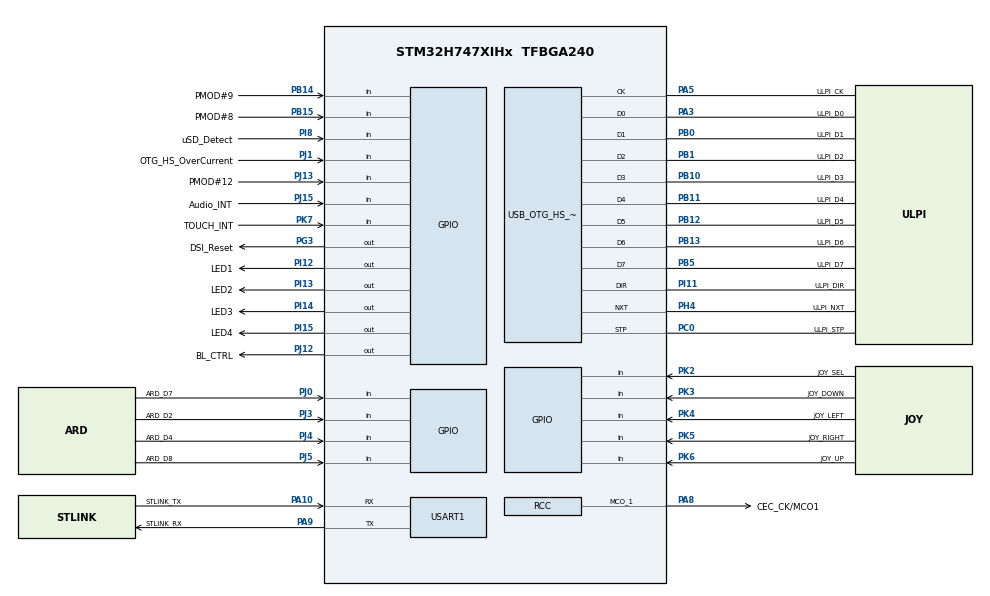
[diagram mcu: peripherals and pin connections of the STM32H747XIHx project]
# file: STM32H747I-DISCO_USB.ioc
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CortexM4.IPs=BDMA,DMA,FATFS_M4\:I,FREERTOS_M4\:I,IWDG2\:I,MDMA,NVIC2\:I,RCC,USB_DEVICE_M4\:I,USB_HOST_M4\:I,WWDG2\:I,DEBUG,PDM2PCM_M4\:I,PWR,RESMGR_UTILITY,SYS_M4\:I,CORTEX_M4\:I,OPENAMP_M4\:I,VREFBUF
CortexM7.IPs=BDMA\:I,DMA\:I,FATFS_M7\:I,FREERTOS_M7\:I,IWDG1\:I,MDMA\:I,NVIC1\:I,RCC\:I,USB_DEVICE_M7\:I,USB_HOST_M7\:I,WWDG1\:I,USART1\:I,CORTEX_M7\:I,DEBUG\:I,PDM2PCM_M7\:I,PWR\:I,RESMGR_UTILITY\:I,SYS\:I,OPENAMP_M7\:I,VREFBUF\:I,USB_OTG_HS\:I
DSI_CKN.Signal=DSIHOST_CKN
DSI_CKP.Signal=DSIHOST_CKP
DSI_D0N.Signal=DSIHOST_D0N
DSI_D0P.Signal=DSIHOST_D0P
DSI_D1N.Signal=DSIHOST_D1N
DSI_D1P.Signal=DSIHOST_D1P
Mcu.Family=STM32H7
Mcu.Name=STM32H747XIHx
Mcu.Package=TFBGA240
NVIC1.OTG_HS_EP1_IN_IRQn=true\:0\:0\:false\:false\:true\:true\:true\:true
NVIC1.OTG_HS_EP1_OUT_IRQn=true\:0\:0\:false\:false\:true\:true\:true\:true
NVIC1.OTG_HS_IRQn=true\:0\:0\:false\:false\:true\:true\:true\:true
NVIC1.PriorityGroup=NVIC_PRIORITYGROUP_4
NVIC2.PriorityGroup=NVIC_PRIORITYGROUP_4
PA0_C.GPIO_Label=ARD_A2
PA0_C.PinAttribute=CortexM4
PA0_C.Signal=ADCx_INP0
PA1.GPIO_Label=ETH_REF_CLK
PA1.PinAttribute=CortexM4
PA1.Signal=ETH_REF_CLK
PA10.GPIO_Label=STLINK_TX
PA10.Mode=Asynchronous
PA10.PinAttribute=CortexM7
PA10.Signal=USART1_RX
PA11.GPIO_Label=PMOD\#1
PA11.PinAttribute=CortexM4
PA11.Signal=SPI2_NSS
PA12.GPIO_Label=SPI2_SCK
PA12.PinAttribute=CortexM4
PA12.Signal=SPI2_SCK
PA1_C.GPIO_Label=ARD_A3
PA1_C.PinAttribute=CortexM4
PA1_C.Signal=ADCx_INP1
PA2.GPIO_Label=ETH_MDIO
PA2.PinAttribute=CortexM4
PA2.Signal=ETH_MDIO
PA3.GPIO_Label=ULPI_D0
PA3.Mode=Device_HS
PA3.PinAttribute=CortexM7
PA3.Signal=USB_OTG_HS_ULPI_D0
PA5.GPIO_Label=ULPI_CK
PA5.Mode=Device_HS
PA5.PinAttribute=CortexM7
PA5.Signal=USB_OTG_HS_ULPI_CK
PA7.GPIO_Label=ETH_CRS_DV
PA7.PinAttribute=CortexM4
PA7.Signal=ETH_CRS_DV
PA8.GPIO_Label=CEC_CK/MCO1
PA8.Mode=Clock-out-1
PA8.PinAttribute=CortexM7
PA8.Signal=RCC_MCO_1
PA9.GPIO_Label=STLINK_RX
PA9.Mode=Asynchronous
PA9.PinAttribute=CortexM7
PA9.Signal=USART1_TX
PB0.GPIO_Label=ULPI_D1
PB0.Mode=Device_HS
PB0.PinAttribute=CortexM7
PB0.Signal=USB_OTG_HS_ULPI_D1
PB1.GPIO_Label=ULPI_D2
PB1.Mode=Device_HS
PB1.PinAttribute=CortexM7
PB1.Signal=USB_OTG_HS_ULPI_D2
PB10.GPIO_Label=ULPI_D3
PB10.Mode=Device_HS
PB10.PinAttribute=CortexM7
PB10.Signal=USB_OTG_HS_ULPI_D3
PB11.GPIO_Label=ULPI_D4
PB11.Mode=Device_HS
PB11.PinAttribute=CortexM7
PB11.Signal=USB_OTG_HS_ULPI_D4
PB12.GPIO_Label=ULPI_D5
PB12.Mode=Device_HS
PB12.PinAttribute=CortexM7
PB12.Signal=USB_OTG_HS_ULPI_D5
PB13.GPIO_Label=ULPI_D6
PB13.Mode=Device_HS
PB13.PinAttribute=CortexM7
PB13.Signal=USB_OTG_HS_ULPI_D6
PB14.GPIO_Label=PMOD\#9
PB14.PinAttribute=Free
PB14.Signal=GPIO_Input
PB15.GPIO_Label=PMOD\#8
PB15.PinAttribute=Free
PB15.Signal=GPIO_Input
PB2.GPIO_Label=QSPI_CLK
PB2.PinAttribute=CortexM4
PB2.Signal=QUADSPI_CLK
PB5.GPIO_Label=ULPI_D7
PB5.Mode=Device_HS
PB5.PinAttribute=CortexM7
PB5.Signal=USB_OTG_HS_ULPI_D7
PB6.GPIO_Label=HDMI_CEC
PB6.PinAttribute=CortexM4
PB6.Signal=CEC
PC0.GPIO_Label=ULPI_STP
PC0.Mode=Device_HS
PC0.PinAttribute=CortexM7
PC0.Signal=USB_OTG_HS_ULPI_STP
PC1.GPIO_Label=ETH_MDC/SAI4_D1
PC1.PinAttribute=CortexM4
PC1.Signal=ETH_MDC
PC10.GPIO_Label=SDIO1_D2
PC10.PinAttribute=CortexM4
PC10.Signal=SDMMC1_D2
PC12.GPIO_Label=SDIO1_CK
PC12.PinAttribute=CortexM4
PC12.Signal=SDMMC1_CK
PC13.GPIO_Label=B2 [Wakeup Button]
PC13.PinAttribute=CortexM4
PC13.Signal=RTC_TAMP1
PC14-OSC32_IN\ (OSC32_IN).GPIO_Label=OSC32_IN
PC14-OSC32_IN\ (OSC32_IN).Mode=LSE-External-Oscillator
PC14-OSC32_IN\ (OSC32_IN).PinAttribute=CortexM7
PC14-OSC32_IN\ (OSC32_IN).Signal=RCC_OSC32_IN
PC15-OSC32_OUT\ (OSC32_OUT).GPIO_Label=OSC32_OUT
PC15-OSC32_OUT\ (OSC32_OUT).Mode=LSE-External-Oscillator
PC15-OSC32_OUT\ (OSC32_OUT).PinAttribute=CortexM7
PC15-OSC32_OUT\ (OSC32_OUT).Signal=RCC_OSC32_OUT
PC2.GPIO_Label=PMOD\#3
PC2.PinAttribute=CortexM4
PC2.Signal=SPI2_MISO
PC2_C.GPIO_Label=ARD_A4
PC2_C.PinAttribute=CortexM4
PC2_C.Signal=ADC3_INP0
PC3.GPIO_Label=PMOD\#2
PC3.PinAttribute=CortexM4
PC3.Signal=SPI2_MOSI
PC3_C.GPIO_Label=ARD_A5
PC3_C.PinAttribute=CortexM4
PC3_C.Signal=ADC3_INP1
PC4.GPIO_Label=ETH_RXD0
PC4.PinAttribute=CortexM4
PC4.Signal=ETH_RXD0
PC5.GPIO_Label=ETH_RXD1
PC5.PinAttribute=CortexM4
PC5.Signal=ETH_RXD1
PC8.GPIO_Label=SDIO1_D0
PC8.PinAttribute=CortexM4
PC8.Signal=SDMMC1_D0
PD0.GPIO_Label=FMC_D2
PD0.PinAttribute=CortexM4
PD0.Signal=FMC_D2_DA2
PD1.GPIO_Label=FMC_D3
PD1.PinAttribute=CortexM4
PD1.Signal=FMC_D3_DA3
PD10.GPIO_Label=FMC_D15
PD10.PinAttribute=CortexM4
PD10.Signal=FMC_D15_DA15
PD11.GPIO_Label=QSPI_BK1_IO0
PD11.PinAttribute=CortexM4
PD11.Signal=QUADSPI_BK1_IO0
PD12.Signal=I2C4_SCL
PD13.Signal=I2C4_SDA
PD14.GPIO_Label=FMC_D0
PD14.PinAttribute=CortexM4
PD14.Signal=FMC_D0_DA0
PD15.GPIO_Label=FMC_D1
PD15.PinAttribute=CortexM4
PD15.Signal=FMC_D1_DA1
PD2.GPIO_Label=SDIO1_CMD
PD2.PinAttribute=CortexM4
PD2.Signal=SDMMC1_CMD
PD7.GPIO_Label=SPDIF_RX0
PD7.PinAttribute=CortexM4
PD7.Signal=SPDIFRX1_IN0
PD8.GPIO_Label=FMC_D13
PD8.PinAttribute=CortexM4
PD8.Signal=FMC_D13_DA13
PD9.GPIO_Label=FMC_D14
PD9.PinAttribute=CortexM4
PD9.Signal=FMC_D14_DA14
PE0.GPIO_Label=FMC_NBL0
PE0.PinAttribute=CortexM4
PE0.Signal=FMC_NBL0
PE1.GPIO_Label=FMC_NBL1
PE1.PinAttribute=CortexM4
PE1.Signal=FMC_NBL1
PE10.GPIO_Label=FMC_D7
PE10.PinAttribute=CortexM4
PE10.Signal=FMC_D7_DA7
PE11.GPIO_Label=FMC_D8
PE11.PinAttribute=CortexM4
PE11.Signal=FMC_D8_DA8
PE12.GPIO_Label=FMC_D9
PE12.PinAttribute=CortexM4
PE12.Signal=FMC_D9_DA9
PE13.GPIO_Label=FMC_D10
PE13.PinAttribute=CortexM4
PE13.Signal=FMC_D10_DA10
PE14.GPIO_Label=FMC_D11
PE14.PinAttribute=CortexM4
PE14.Signal=FMC_D11_DA11
PE15.GPIO_Label=FMC_D12
PE15.PinAttribute=CortexM4
PE15.Signal=FMC_D12_DA12
PE3.GPIO_Label=SAI1_SD_B
PE3.PinAttribute=CortexM4
PE3.Signal=SAI1_SD_B
PE4.GPIO_Label=SAI1_FS_A
PE4.PinAttribute=CortexM4
PE4.Signal=SAI1_FS_A
PE5.GPIO_Label=SAI1_SCK_A
PE5.PinAttribute=CortexM4
PE5.Signal=SAI1_SCK_A
PE6.GPIO_Label=SAI1_SD_A
PE6.PinAttribute=CortexM4
PE6.Signal=SAI1_SD_A
PE7.GPIO_Label=FMC_D4
PE7.PinAttribute=CortexM4
PE7.Signal=FMC_D4_DA4
PE8.GPIO_Label=FMC_D5
PE8.PinAttribute=CortexM4
PE8.Signal=FMC_D5_DA5
PE9.GPIO_Label=FMC_D6
PE9.PinAttribute=CortexM4
PE9.Signal=FMC_D6_DA6
PF0.GPIO_Label=FMC_A0
PF0.PinAttribute=CortexM4
PF0.Signal=FMC_A0
PF1.GPIO_Label=FMC_A1
PF1.PinAttribute=CortexM4
PF1.Signal=FMC_A1
PF10.GPIO_Label=ARD_A1
PF10.PinAttribute=CortexM4
PF10.Signal=ADC3_INP6
PF11.GPIO_Label=FMC_SDRAS
PF11.PinAttribute=CortexM4
PF11.Signal=FMC_SDNRAS
PF12.GPIO_Label=FMC_A6
PF12.PinAttribute=CortexM4
PF12.Signal=FMC_A6
PF13.GPIO_Label=FMC_A7
PF13.PinAttribute=CortexM4
PF13.Signal=FMC_A7
PF14.GPIO_Label=FMC_A8
PF14.PinAttribute=CortexM4
PF14.Signal=FMC_A8
PF15.GPIO_Label=FMC_A9
PF15.PinAttribute=CortexM4
PF15.Signal=FMC_A9
PF2.GPIO_Label=FMC_A2
PF2.PinAttribute=CortexM4
PF2.Signal=FMC_A2
PF3.GPIO_Label=FMC_A3
PF3.PinAttribute=CortexM4
PF3.Signal=FMC_A3
PF4.GPIO_Label=FMC_A4
PF4.PinAttribute=CortexM4
PF4.Signal=FMC_A4
PF5.GPIO_Label=FMC_A5
PF5.PinAttribute=CortexM4
PF5.Signal=FMC_A5
PF6.GPIO_Label=QSPI_BK1_IO3
PF6.PinAttribute=CortexM4
PF6.Signal=QUADSPI_BK1_IO3
PF7.GPIO_Label=QSPI_BK1_IO2
PF7.PinAttribute=CortexM4
PF7.Signal=QUADSPI_BK1_IO2
PF8.GPIO_Label=PMOD\#14/ARD_D3
PF8.PinAttribute=CortexM4
PF8.Signal=S_TIM13_CH1
PF9.GPIO_Label=QSPI_BK1_IO1
PF9.PinAttribute=CortexM4
PF9.Signal=QUADSPI_BK1_IO1
PG0.GPIO_Label=FMC_A10
PG0.PinAttribute=CortexM4
PG0.Signal=FMC_A10
PG1.GPIO_Label=FMC_A11
PG1.PinAttribute=CortexM4
PG1.Signal=FMC_A11
PG11.GPIO_Label=ETH_TX_EN
PG11.PinAttribute=CortexM4
PG11.Signal=ETH_TX_EN
PG12.GPIO_Label=ETH_TXD1
PG12.PinAttribute=CortexM4
PG12.Signal=ETH_TXD1
PG13.GPIO_Label=ETH_TXD0
PG13.PinAttribute=CortexM4
PG13.Signal=ETH_TXD0
PG14.GPIO_Label=QSPI_BK2_IO3
PG14.PinAttribute=CortexM4
PG14.Signal=QUADSPI_BK2_IO3
PG15.GPIO_Label=FMC_SDCAS
PG15.PinAttribute=CortexM4
PG15.Signal=FMC_SDNCAS
PG2.GPIO_Label=FMC_A12
PG2.PinAttribute=CortexM4
PG2.Signal=FMC_A12
PG3.GPIO_Label=DSI_Reset
PG3.PinAttribute=Free
PG3.Signal=GPIO_Output
PG4.GPIO_Label=FMC_BA0
PG4.PinAttribute=CortexM4
PG4.Signal=FMC_A14_BA0
PG6.GPIO_Label=QSPI_BK1_NCS
PG6.PinAttribute=CortexM4
PG6.Signal=QUADSPI_BK1_NCS
PG7.GPIO_Label=SAI1_MCLK_A
PG7.PinAttribute=CortexM4
PG7.Signal=SAI1_MCLK_A
PG8.GPIO_Label=FMC_SDCLK
PG8.PinAttribute=CortexM4
PG8.Signal=FMC_SDCLK
PG9.GPIO_Label=QSPI_BK2_IO2
PG9.PinAttribute=CortexM4
PG9.Signal=QUADSPI_BK2_IO2
PH0-OSC_IN\ (PH0).GPIO_Label=OSC_IN
PH0-OSC_IN\ (PH0).Mode=HSE-External-Oscillator
PH0-OSC_IN\ (PH0).PinAttribute=CortexM7
PH0-OSC_IN\ (PH0).Signal=RCC_OSC_IN
PH1-OSC_OUT\ (PH1).GPIO_Label=OSC_OUT
PH1-OSC_OUT\ (PH1).Mode=HSE-External-Oscillator
PH1-OSC_OUT\ (PH1).PinAttribute=CortexM7
PH1-OSC_OUT\ (PH1).Signal=RCC_OSC_OUT
PH10.GPIO_Label=FMC_D18
PH10.PinAttribute=CortexM4
PH10.Signal=FMC_D18
PH11.GPIO_Label=FMC_D19
PH11.PinAttribute=CortexM4
PH11.Signal=FMC_D19
PH12.GPIO_Label=FMC_D20
PH12.PinAttribute=CortexM4
PH12.Signal=FMC_D20
PH13.GPIO_Label=FMC_D21
PH13.PinAttribute=CortexM4
PH13.Signal=FMC_D21
PH14.GPIO_Label=FMC_D22
PH14.PinAttribute=CortexM4
PH14.Signal=FMC_D22
PH15.GPIO_Label=FMC_D23
PH15.PinAttribute=CortexM4
PH15.Signal=FMC_D23
PH2.GPIO_Label=QSPI_BK2_IO0
PH2.PinAttribute=CortexM4
PH2.Signal=QUADSPI_BK2_IO0
PH3.GPIO_Label=QSPI_BK2_IO1
PH3.PinAttribute=CortexM4
PH3.Signal=QUADSPI_BK2_IO1
PH4.GPIO_Label=ULPI_NXT
PH4.Mode=Device_HS
PH4.PinAttribute=CortexM7
PH4.Signal=USB_OTG_HS_ULPI_NXT
PH5.GPIO_Label=FMC_SDNWE
PH5.PinAttribute=CortexM4
PH5.Signal=FMC_SDNWE
PH6.GPIO_Label=FMC_SDNE1
PH6.PinAttribute=CortexM4
PH6.Signal=FMC_SDNE1
PH7.GPIO_Label=FMC_SDCKE1
PH7.PinAttribute=CortexM4
PH7.Signal=FMC_SDCKE1
PH8.GPIO_Label=FMC_D16
PH8.PinAttribute=CortexM4
PH8.Signal=FMC_D16
PH9.GPIO_Label=FMC_D17
PH9.PinAttribute=CortexM4
PH9.Signal=FMC_D17
PI0.GPIO_Label=FMC_D24
PI0.PinAttribute=CortexM4
PI0.Signal=FMC_D24
PI1.GPIO_Label=FMC_D25
PI1.PinAttribute=CortexM4
PI1.Signal=FMC_D25
PI10.GPIO_Label=FMC_D31
PI10.PinAttribute=CortexM4
PI10.Signal=FMC_D31
PI11.GPIO_Label=ULPI_DIR
PI11.Mode=Device_HS
PI11.PinAttribute=CortexM7
PI11.Signal=USB_OTG_HS_ULPI_DIR
PI12.GPIO_Label=LED1
PI12.PinAttribute=Free
PI12.Signal=GPIO_Output
PI13.GPIO_Label=LED2
PI13.PinAttribute=Free
PI13.Signal=GPIO_Output
PI14.GPIO_Label=LED3
PI14.PinAttribute=Free
PI14.Signal=GPIO_Output
PI15.GPIO_Label=LED4
PI15.PinAttribute=Free
PI15.Signal=GPIO_Output
PI2.GPIO_Label=FMC_D26
PI2.PinAttribute=CortexM4
PI2.Signal=FMC_D26
PI3.GPIO_Label=FMC_D27
PI3.PinAttribute=CortexM4
PI3.Signal=FMC_D27
PI4.GPIO_Label=FMC_NBL2
PI4.PinAttribute=CortexM4
PI4.Signal=FMC_NBL2
PI5.GPIO_Label=FMC_NBL3
PI5.PinAttribute=CortexM4
PI5.Signal=FMC_NBL3
PI6.GPIO_Label=FMC_D28
PI6.PinAttribute=CortexM4
PI6.Signal=FMC_D28
PI7.GPIO_Label=FMC_D29
PI7.PinAttribute=CortexM4
PI7.Signal=FMC_D29
PI8.GPIO_Label=uSD_Detect
PI8.PinAttribute=Free
PI8.Signal=GPIO_Input
PI9.GPIO_Label=FMC_D30
PI9.PinAttribute=CortexM4
PI9.Signal=FMC_D30
PJ0.GPIO_Label=ARD_D7
PJ0.PinAttribute=Free
PJ0.Signal=GPIO_Input
PJ1.GPIO_Label=OTG_HS_OverCurrent
PJ1.PinAttribute=Free
PJ1.Signal=GPIO_Input
PJ10.GPIO_Label=ARD_D11
PJ10.PinAttribute=CortexM4
PJ10.Signal=SPI5_MOSI
PJ11.GPIO_Label=ARD_D12
PJ11.PinAttribute=CortexM4
PJ11.Signal=SPI5_MISO
PJ12.GPIO_Label=BL_CTRL
PJ12.PinAttribute=Free
PJ12.Signal=GPIO_Output
PJ13.GPIO_Label=PMOD\#12
PJ13.PinAttribute=Free
PJ13.Signal=GPIO_Input
PJ15.GPIO_Label=Audio_INT
PJ15.PinAttribute=Free
PJ15.Signal=GPIO_Input
PJ2.GPIO_Label=DSI_TE
PJ2.Signal=DSIHOST_TE
PJ3.GPIO_Label=ARD_D2
PJ3.PinAttribute=Free
PJ3.Signal=GPIO_Input
PJ4.GPIO_Label=ARD_D4
PJ4.PinAttribute=Free
PJ4.Signal=GPIO_Input
PJ5.GPIO_Label=ARD_D8
PJ5.PinAttribute=Free
PJ5.Signal=GPIO_Input
PJ6.GPIO_Label=ARD_D9
PJ6.PinAttribute=CortexM4
PJ6.Signal=S_TIM8_CH2
PJ7.GPIO_Label=ARD_D6
PJ7.PinAttribute=CortexM4
PJ7.Signal=TIM8_CH2N
PJ8.GPIO_Label=ARD_D1
PJ8.PinAttribute=CortexM4
PJ8.Signal=UART8_TX
PJ9.GPIO_Label=ARD_D0
PJ9.PinAttribute=CortexM4
PJ9.Signal=UART8_RX
PK0.GPIO_Label=ARD_D13
PK0.PinAttribute=CortexM4
PK0.Signal=SPI5_SCK
PK1.GPIO_Label=ARD_D10
PK1.PinAttribute=CortexM4
PK1.Signal=SPI5_NSS
PK2.GPIO_Label=JOY_SEL
PK2.PinAttribute=Free
PK2.Signal=GPIO_Input
PK3.GPIO_Label=JOY_DOWN
PK3.PinAttribute=Free
PK3.Signal=GPIO_Input
PK4.GPIO_Label=JOY_LEFT
PK4.PinAttribute=Free
PK4.Signal=GPIO_Input
PK5.GPIO_Label=JOY_RIGHT
PK5.PinAttribute=Free
PK5.Signal=GPIO_Input
PK6.GPIO_Label=JOY_UP
PK6.PinAttribute=Free
PK6.Signal=GPIO_Input
PK7.GPIO_Label=TOUCH_INT
PK7.PinAttribute=Free
PK7.Signal=GPIO_Input
ProjectManager.HeapSize=M4-0x200,M7-0x200
ProjectManager.StackSize=M4-0x400,M7-0x400
ProjectManager.TargetToolchain=STM32CubeIDE
RCC.ADCFreq_Value=75000000
RCC.APB1Freq_Value=64000000
RCC.APB2Freq_Value=64000000
RCC.APB3Freq_Value=64000000
RCC.APB4Freq_Value=64000000
RCC.CortexFreq_Value=64000000
RCC.DIVM1=5
RCC.DIVM2=2
RCC.DIVN1=48
RCC.DIVN2=12
RCC.DIVQ1=5
RCC.HCLKFreq_Value=64000000
RCC.PLL2FRACN=0
RCC.PLL3FRACN=0
RCC.PLLFRACN=0
RCC.PWR_Regulator_Voltage_Scale=PWR_REGULATOR_VOLTAGE_SCALE1
RCC.SYSCLKFreq_VALUE=64000000
RCC.SupplySource=PWR_DIRECT_SMPS_SUPPLY
RCC.USBFreq_Value=48000000
SH.ADCx_INP0.0=ADC1_INP0
SH.ADCx_INP1.0=ADC1_INP1
SH.FMC_A0.0=FMC_A0
SH.FMC_A1.0=FMC_A1
SH.FMC_A10.0=FMC_A10
SH.FMC_A11.0=FMC_A11
SH.FMC_A12.0=FMC_A12
SH.FMC_A14_BA0.0=FMC_BA0
SH.FMC_A2.0=FMC_A2
SH.FMC_A3.0=FMC_A3
SH.FMC_A4.0=FMC_A4
SH.FMC_A5.0=FMC_A5
SH.FMC_A6.0=FMC_A6
SH.FMC_A7.0=FMC_A7
SH.FMC_A8.0=FMC_A8
SH.FMC_A9.0=FMC_A9
SH.FMC_D0_DA0.0=FMC_D0
SH.FMC_D10_DA10.0=FMC_D10
SH.FMC_D11_DA11.0=FMC_D11
SH.FMC_D12_DA12.0=FMC_D12
SH.FMC_D13_DA13.0=FMC_D13
SH.FMC_D14_DA14.0=FMC_D14
SH.FMC_D15_DA15.0=FMC_D15
SH.FMC_D16.0=FMC_D16
SH.FMC_D17.0=FMC_D17
SH.FMC_D18.0=FMC_D18
SH.FMC_D19.0=FMC_D19
SH.FMC_D1_DA1.0=FMC_D1
SH.FMC_D20.0=FMC_D20
SH.FMC_D21.0=FMC_D21
SH.FMC_D22.0=FMC_D22
SH.FMC_D23.0=FMC_D23
SH.FMC_D24.0=FMC_D24
SH.FMC_D25.0=FMC_D25
SH.FMC_D26.0=FMC_D26
SH.FMC_D27.0=FMC_D27
SH.FMC_D28.0=FMC_D28
SH.FMC_D29.0=FMC_D29
SH.FMC_D2_DA2.0=FMC_D2
SH.FMC_D30.0=FMC_D30
SH.FMC_D31.0=FMC_D31
SH.FMC_D3_DA3.0=FMC_D3
SH.FMC_D4_DA4.0=FMC_D4
SH.FMC_D5_DA5.0=FMC_D5
SH.FMC_D6_DA6.0=FMC_D6
SH.FMC_D7_DA7.0=FMC_D7
SH.FMC_D8_DA8.0=FMC_D8
SH.FMC_D9_DA9.0=FMC_D9
SH.FMC_NBL0.0=FMC_NBL0
SH.FMC_NBL1.0=FMC_NBL1
SH.FMC_NBL2.0=FMC_NBL2
SH.FMC_NBL3.0=FMC_NBL3
SH.FMC_SDCLK.0=FMC_SDCLK
SH.FMC_SDNCAS.0=FMC_SDNCAS
SH.FMC_SDNRAS.0=FMC_SDNRAS
SH.FMC_SDNWE.0=FMC_SDNWE
SH.S_TIM13_CH1.0=TIM13_CH1
SH.S_TIM8_CH2.0=TIM8_CH2
USART1.VirtualMode-Asynchronous=VM_ASYNC
USB_DEVICE_M7.CLASS_NAME_HS=CDC
USB_DEVICE_M7.VirtualMode-CDC_HS=Cdc
USB_DEVICE_M7.VirtualModeHS=Cdc_HS
USB_OTG_HS.VirtualMode-Device_HS=Device_HS
VP_SYS_M4_VS_Systick.Mode=SysTick
VP_USB_DEVICE_M7_VS_USB_DEVICE_CDC_HS.Mode=CDC_HS
board=STM32H747I-DISCO

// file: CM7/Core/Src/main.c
/* USER CODE BEGIN Header */
/**
  ******************************************************************************
  * @file           : main.c
  * @brief          : Main program body
  ******************************************************************************
  * @attention
  *
  * Copyright (c) 2022 STMicroelectronics.
  * All rights reserved.
  *
  * This software is licensed under terms that can be found in the LICENSE file
  * in the root directory of this software component.
  * If no LICENSE file comes with this software, it is provided AS-IS.
  *
  ******************************************************************************
  */
/* USER CODE END Header */
#include "main.h"
#include "usb_device.h"

/* USER CODE BEGIN PD */

#ifndef HSEM_ID_0
#define HSEM_ID_0 (0U) /* HW semaphore 0*/
#endif
/* USER CODE END PD */

UART_HandleTypeDef huart1;

void SystemClock_Config(void);
static void MX_GPIO_Init(void);
static void MX_USART1_UART_Init(void);

int main(void)
{
  /* USER CODE BEGIN 1 */
	uint8_t buffer[] = "Hello World\r\n";
  /* USER CODE END 1 */
/* USER CODE BEGIN Boot_Mode_Sequence_0 */
  int32_t timeout;
/* USER CODE END Boot_Mode_Sequence_0 */

/* USER CODE BEGIN Boot_Mode_Sequence_1 */
  /* Wait until CPU2 boots and enters in stop mode or timeout*/

/* USER CODE END Boot_Mode_Sequence_1 */
  /* MCU Configuration--------------------------------------------------------*/

  /* Reset of all peripherals, Initializes the Flash interface and the Systick. */
  HAL_Init();

  /* Configure the system clock */
  SystemClock_Config();
/* USER CODE BEGIN Boot_Mode_Sequence_2 */
/* When system initialization is finished, Cortex-M7 will release Cortex-M4 by means of
HSEM notification */
/*HW semaphore Clock enable*/
__HAL_RCC_HSEM_CLK_ENABLE();
/*Take HSEM */
HAL_HSEM_FastTake(HSEM_ID_0);
/*Release HSEM in order to notify the CPU2(CM4)*/
HAL_HSEM_Release(HSEM_ID_0,0);
/* wait until CPU2 wakes up from stop mode */

/* USER CODE END Boot_Mode_Sequence_2 */

  /* USER CODE BEGIN SysInit */
extern uint8_t CDC_Transmit_HS(uint8_t* Buf, uint16_t Len);
  /* USER CODE END SysInit */

  /* Initialize all configured peripherals */
  MX_GPIO_Init();
  MX_USART1_UART_Init();
  MX_USB_DEVICE_Init();

  /* Infinite loop */
  while (1)
  {
	  CDC_Transmit_HS(buffer, sizeof(buffer));
	  HAL_Delay(1000);
  }
}

void SystemClock_Config(void)
{
  RCC_OscInitTypeDef RCC_OscInitStruct = {0};
  RCC_ClkInitTypeDef RCC_ClkInitStruct = {0};

  /** Supply configuration update enable
  */
  HAL_PWREx_ConfigSupply(PWR_DIRECT_SMPS_SUPPLY);

  /** Configure the main internal regulator output voltage
  */
  __HAL_PWR_VOLTAGESCALING_CONFIG(PWR_REGULATOR_VOLTAGE_SCALE1);

  //while(!__HAL_PWR_GET_FLAG(PWR_FLAG_VOSRDY)) {}

  /** Initializes the RCC Oscillators according to the specified parameters
  * in the RCC_OscInitTypeDef structure.
  */
  RCC_OscInitStruct.OscillatorType = RCC_OSCILLATORTYPE_HSI|RCC_OSCILLATORTYPE_HSE;
  RCC_OscInitStruct.HSEState = RCC_HSE_ON;
  RCC_OscInitStruct.HSIState = RCC_HSI_DIV1;
  RCC_OscInitStruct.HSICalibrationValue = RCC_HSICALIBRATION_DEFAULT;
  RCC_OscInitStruct.PLL.PLLState = RCC_PLL_ON;
  RCC_OscInitStruct.PLL.PLLSource = RCC_PLLSOURCE_HSE;
  RCC_OscInitStruct.PLL.PLLM = 5;
  RCC_OscInitStruct.PLL.PLLN = 48;
  RCC_OscInitStruct.PLL.PLLP = 2;
  RCC_OscInitStruct.PLL.PLLQ = 5;
  RCC_OscInitStruct.PLL.PLLR = 2;
  RCC_OscInitStruct.PLL.PLLRGE = RCC_PLL1VCIRANGE_2;
  RCC_OscInitStruct.PLL.PLLVCOSEL = RCC_PLL1VCOWIDE;
  RCC_OscInitStruct.PLL.PLLFRACN = 0;
  if (HAL_RCC_OscConfig(&RCC_OscInitStruct) != HAL_OK)
  {
    Error_Handler();
  }

  /** Initializes the CPU, AHB and APB buses clocks
  */
  RCC_ClkInitStruct.ClockType = RCC_CLOCKTYPE_HCLK|RCC_CLOCKTYPE_SYSCLK
                              |RCC_CLOCKTYPE_PCLK1|RCC_CLOCKTYPE_PCLK2
                              |RCC_CLOCKTYPE_D3PCLK1|RCC_CLOCKTYPE_D1PCLK1;
  RCC_ClkInitStruct.SYSCLKSource = RCC_SYSCLKSOURCE_HSI;
  RCC_ClkInitStruct.SYSCLKDivider = RCC_SYSCLK_DIV1;
  RCC_ClkInitStruct.AHBCLKDivider = RCC_HCLK_DIV1;
  RCC_ClkInitStruct.APB3CLKDivider = RCC_APB3_DIV1;
  RCC_ClkInitStruct.APB1CLKDivider = RCC_APB1_DIV1;
  RCC_ClkInitStruct.APB2CLKDivider = RCC_APB2_DIV1;
  RCC_ClkInitStruct.APB4CLKDivider = RCC_APB4_DIV1;

  if (HAL_RCC_ClockConfig(&RCC_ClkInitStruct, FLASH_LATENCY_0) != HAL_OK)
  {
    Error_Handler();
  }
  HAL_RCC_MCOConfig(RCC_MCO1, RCC_MCO1SOURCE_HSI, RCC_MCODIV_1);
}

static void MX_USART1_UART_Init(void)
{

  huart1.Instance = USART1;
  huart1.Init.BaudRate = 115200;
  huart1.Init.WordLength = UART_WORDLENGTH_8B;
  huart1.Init.StopBits = UART_STOPBITS_1;
  huart1.Init.Parity = UART_PARITY_NONE;
  huart1.Init.Mode = UART_MODE_TX_RX;
  huart1.Init.HwFlowCtl = UART_HWCONTROL_NONE;
  huart1.Init.OverSampling = UART_OVERSAMPLING_16;
  huart1.Init.OneBitSampling = UART_ONE_BIT_SAMPLE_DISABLE;
  huart1.Init.ClockPrescaler = UART_PRESCALER_DIV1;
  huart1.AdvancedInit.AdvFeatureInit = UART_ADVFEATURE_NO_INIT;
  if (HAL_UART_Init(&huart1) != HAL_OK)
  {
    Error_Handler();
  }
  if (HAL_UARTEx_SetTxFifoThreshold(&huart1, UART_TXFIFO_THRESHOLD_1_8) != HAL_OK)
  {
    Error_Handler();
  }
  if (HAL_UARTEx_SetRxFifoThreshold(&huart1, UART_RXFIFO_THRESHOLD_1_8) != HAL_OK)
  {
    Error_Handler();
  }
  if (HAL_UARTEx_DisableFifoMode(&huart1) != HAL_OK)
  {
    Error_Handler();
  }

}

static void MX_GPIO_Init(void)
{
  GPIO_InitTypeDef GPIO_InitStruct = {0};

  /* GPIO Ports Clock Enable */
  __HAL_RCC_GPIOB_CLK_ENABLE();
  __HAL_RCC_GPIOC_CLK_ENABLE();
  __HAL_RCC_GPIOA_CLK_ENABLE();
  __HAL_RCC_GPIOI_CLK_ENABLE();
  __HAL_RCC_GPIOH_CLK_ENABLE();

  /*Configure GPIO pin : CEC_CK_MCO1_Pin */
  GPIO_InitStruct.Pin = CEC_CK_MCO1_Pin;
  GPIO_InitStruct.Mode = GPIO_MODE_AF_PP;
  GPIO_InitStruct.Pull = GPIO_NOPULL;
  GPIO_InitStruct.Speed = GPIO_SPEED_FREQ_LOW;
  GPIO_InitStruct.Alternate = GPIO_AF0_MCO;
  HAL_GPIO_Init(CEC_CK_MCO1_GPIO_Port, &GPIO_InitStruct);

}

void Error_Handler(void)
{
  __disable_irq();
  while (1)
  {
  }
}
